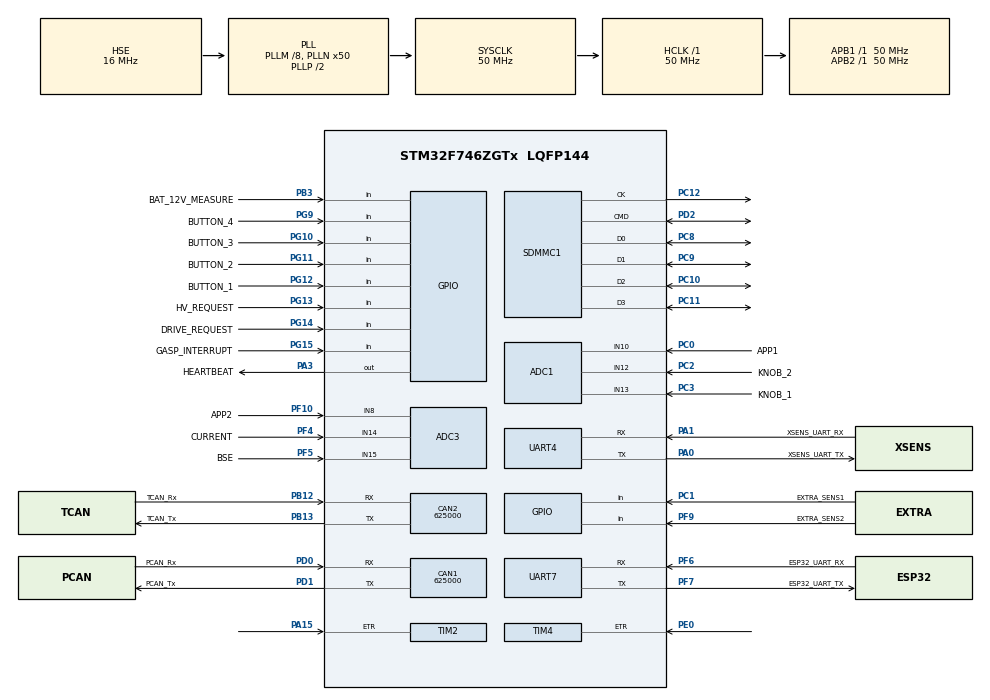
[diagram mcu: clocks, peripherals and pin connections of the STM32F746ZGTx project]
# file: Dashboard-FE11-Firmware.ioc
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ADC1.Channel-0\#ChannelRegularConversion=ADC_CHANNEL_10
ADC1.ClockPrescaler=ADC_CLOCK_SYNC_PCLK_DIV4
ADC1.NbrOfConversionFlag=1
ADC1.Rank-0\#ChannelRegularConversion=1
ADC1.SamplingTime-0\#ChannelRegularConversion=ADC_SAMPLETIME_3CYCLES
ADC1.master=1
ADC3.Channel-0\#ChannelRegularConversion=ADC_CHANNEL_14
ADC3.ClockPrescaler=ADC_CLOCK_SYNC_PCLK_DIV4
ADC3.NbrOfConversionFlag=1
ADC3.Rank-0\#ChannelRegularConversion=1
ADC3.SamplingTime-0\#ChannelRegularConversion=ADC_SAMPLETIME_3CYCLES
CAN1.BS1=CAN_BS1_3TQ
CAN1.BS2=CAN_BS2_1TQ
CAN1.CalculateBaudRate=625000
CAN1.CalculateTimeBit=1600
CAN1.CalculateTimeQuantum=320.0
CAN2.BS1=CAN_BS1_3TQ
CAN2.BS2=CAN_BS2_1TQ
CAN2.CalculateBaudRate=625000
CAN2.CalculateTimeBit=1600
CAN2.CalculateTimeQuantum=320.0
Mcu.Family=STM32F7
Mcu.Name=STM32F746ZGTx
Mcu.Package=LQFP144
NVIC.CAN1_RX0_IRQn=true\:0\:0\:false\:false\:true\:true\:true\:true
NVIC.CAN2_RX0_IRQn=true\:0\:0\:false\:false\:true\:true\:true\:true
NVIC.PriorityGroup=NVIC_PRIORITYGROUP_4
PA0/WKUP.GPIO_Label=XSENS_UART_TX
PA0/WKUP.Mode=Asynchronous
PA0/WKUP.Signal=UART4_TX
PA1.GPIO_Label=XSENS_UART_RX
PA1.Mode=Asynchronous
PA1.Signal=UART4_RX
PA13.Mode=Serial_Wire
PA13.Signal=SYS_JTMS-SWDIO
PA14.Mode=Serial_Wire
PA14.Signal=SYS_JTCK-SWCLK
PA15.Signal=S_TIM2_CH1_ETR
PA3.GPIO_Label=HEARTBEAT
PA3.Signal=GPIO_Output
PB12.GPIO_Label=TCAN_Rx
PB12.Mode=CAN_Activate
PB12.Signal=CAN2_RX
PB13.GPIO_Label=TCAN_Tx
PB13.Mode=CAN_Activate
PB13.Signal=CAN2_TX
PB3.GPIO_Label=BAT_12V_MEASURE
PB3.Signal=GPIO_Input
PC0.GPIO_Label=APP1
PC0.Signal=ADCx_IN10
PC1.GPIO_Label=EXTRA_SENS1
PC1.Signal=GPIO_Input
PC10.Mode=mmc_4_bits_Wide_bus
PC10.Signal=SDMMC1_D2
PC11.Mode=mmc_4_bits_Wide_bus
PC11.Signal=SDMMC1_D3
PC12.Mode=mmc_4_bits_Wide_bus
PC12.Signal=SDMMC1_CK
PC2.GPIO_Label=KNOB_2
PC2.Signal=ADCx_IN12
PC3.GPIO_Label=KNOB_1
PC3.Signal=ADCx_IN13
PC8.Mode=mmc_4_bits_Wide_bus
PC8.Signal=SDMMC1_D0
PC9.Mode=mmc_4_bits_Wide_bus
PC9.Signal=SDMMC1_D1
PD0.GPIO_Label=PCAN_Rx
PD0.Mode=CAN_Activate
PD0.Signal=CAN1_RX
PD1.GPIO_Label=PCAN_Tx
PD1.Mode=CAN_Activate
PD1.Signal=CAN1_TX
PD2.Mode=mmc_4_bits_Wide_bus
PD2.Signal=SDMMC1_CMD
PE0.Signal=S_TIM4_ETR
PF10.GPIO_Label=APP2
PF10.Mode=IN8
PF10.Signal=ADC3_IN8
PF4.GPIO_Label=CURRENT
PF4.Mode=IN14
PF4.Signal=ADC3_IN14
PF5.GPIO_Label=BSE
PF5.Mode=IN15
PF5.Signal=ADC3_IN15
PF6.GPIO_Label=ESP32_UART_RX
PF6.Mode=Asynchronous
PF6.Signal=UART7_RX
PF7.GPIO_Label=ESP32_UART_TX
PF7.Mode=Asynchronous
PF7.Signal=UART7_TX
PF9.GPIO_Label=EXTRA_SENS2
PF9.Signal=GPIO_Input
PG10.GPIO_Label=BUTTON_3
PG10.Signal=GPIO_Input
PG11.GPIO_Label=BUTTON_2
PG11.Signal=GPIO_Input
PG12.GPIO_Label=BUTTON_1
PG12.Signal=GPIO_Input
PG13.GPIO_Label=HV_REQUEST
PG13.Signal=GPIO_Input
PG14.GPIO_Label=DRIVE_REQUEST
PG14.Signal=GPIO_Input
PG15.GPIO_Label=GASP_INTERRUPT
PG15.Signal=GPIO_Input
PG9.GPIO_Label=BUTTON_4
PG9.Signal=GPIO_Input
PH0/OSC_IN.Mode=HSE-External-Oscillator
PH0/OSC_IN.Signal=RCC_OSC_IN
PH1/OSC_OUT.Mode=HSE-External-Oscillator
PH1/OSC_OUT.Signal=RCC_OSC_OUT
ProjectManager.HeapSize=0x200
ProjectManager.StackSize=0x400
ProjectManager.TargetToolchain=STM32CubeIDE
RCC.AHBFreq_Value=50000000
RCC.APB1Freq_Value=50000000
RCC.APB1TimFreq_Value=50000000
RCC.APB2Freq_Value=50000000
RCC.APB2TimFreq_Value=50000000
RCC.CECClockSelection=RCC_CECCLKSOURCE_HSI
RCC.CortexFreq_Value=50000000
RCC.HCLKFreq_Value=50000000
RCC.HSE_VALUE=16000000
RCC.HSI_VALUE=16000000
RCC.I2SCLockSelection=RCC_I2SCLKSOURCE_PLLI2S
RCC.OscillatorType=OscillatorTypeHSI|OscillatorTypeLSI|OscillatorTypeHSE|OscillatorTypeLSE
RCC.PLLM=8
RCC.PLLN=50
RCC.PLLSourceVirtual=RCC_PLLSOURCE_HSE
RCC.RTCClockSelection=RCC_RTCCLKSOURCE_LSI
RCC.SYSCLKFreq_VALUE=50000000
RCC.SYSCLKSource=RCC_SYSCLKSOURCE_PLLCLK
RCC.USBFreq_Value=50000000
RCC.VCOOutputFreq_Value=100000000
SH.ADCx_IN10.0=ADC1_IN10,IN10
SH.ADCx_IN12.0=ADC1_IN12,IN12
SH.ADCx_IN13.0=ADC1_IN13,IN13
SH.S_TIM2_CH1_ETR.0=TIM2_ETR,TriggerSource_ETR
SH.S_TIM4_ETR.0=TIM4_ETR,TriggerSource_ETR
VP_TIM2_VS_ControllerModeClock.Mode=Clock Mode
VP_TIM4_VS_ControllerModeClock.Mode=Clock Mode
board=custom

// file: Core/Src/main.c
/* USER CODE BEGIN Header */
/**
  ******************************************************************************
  * @file           : main.c
  * @brief          : Main program body
  ******************************************************************************
  * @attention
  *
  * Copyright (c) 2024 STMicroelectronics.
  * All rights reserved.
  *
  * This software is licensed under terms that can be found in the LICENSE file
  * in the root directory of this software component.
  * If no LICENSE file comes with this software, it is provided AS-IS.
  *
  ******************************************************************************
  */
/* USER CODE END Header */
#include "main.h"

ADC_HandleTypeDef hadc1;
ADC_HandleTypeDef hadc3;

CAN_HandleTypeDef hcan1;
CAN_HandleTypeDef hcan2;

CAN_RxHeaderTypeDef RxHeader;

MMC_HandleTypeDef hmmc1;

TIM_HandleTypeDef htim2;
TIM_HandleTypeDef htim4;

UART_HandleTypeDef huart4;
UART_HandleTypeDef huart7;

/* USER CODE BEGIN PV */
void HAL_CAN_RxFifo0MsgPendingCallback(CAN_HandleTypeDef *hcan) {
	HAL_CAN_GetRxMessage(&hcan1, CAN_RX_FIFO0, RxHeader, RxHeader);
		HAL_GPIO_TogglePin(GPIOB, GPIO_PIN_1);
}
/* USER CODE END PV */

void SystemClock_Config(void);
static void MX_GPIO_Init(void);
static void MX_UART4_Init(void);
static void MX_ADC1_Init(void);
static void MX_ADC3_Init(void);
static void MX_CAN1_Init(void);
static void MX_CAN2_Init(void);
static void MX_SDMMC1_MMC_Init(void);
static void MX_TIM2_Init(void);
static void MX_TIM4_Init(void);
static void MX_UART7_Init(void);

int main(void)
{

  /* MCU Configuration--------------------------------------------------------*/

  /* Reset of all peripherals, Initializes the Flash interface and the Systick. */
  HAL_Init();

  /* Configure the system clock */
  SystemClock_Config();

  /* Initialize all configured peripherals */
  MX_GPIO_Init();
  MX_UART4_Init();
  MX_ADC1_Init();
  MX_ADC3_Init();
  MX_CAN1_Init();
  MX_CAN2_Init();
  MX_SDMMC1_MMC_Init();
  MX_TIM2_Init();
  MX_TIM4_Init();
  MX_UART7_Init();

  /* Infinite loop */
  while (1)
  {

  }
}

void SystemClock_Config(void)
{
  RCC_OscInitTypeDef RCC_OscInitStruct = {0};
  RCC_ClkInitTypeDef RCC_ClkInitStruct = {0};

  /** Configure the main internal regulator output voltage
  */
  __HAL_RCC_PWR_CLK_ENABLE();
  __HAL_PWR_VOLTAGESCALING_CONFIG(PWR_REGULATOR_VOLTAGE_SCALE3);

  /** Initializes the RCC Oscillators according to the specified parameters
  * in the RCC_OscInitTypeDef structure.
  */
  RCC_OscInitStruct.OscillatorType = OscillatorTypeHSI|OscillatorTypeLSI
                              |OscillatorTypeHSE|OscillatorTypeLSE;
  RCC_OscInitStruct.HSEState = RCC_HSE_ON;
  RCC_OscInitStruct.PLL.PLLState = RCC_PLL_ON;
  RCC_OscInitStruct.PLL.PLLSource = RCC_PLLSOURCE_HSE;
  RCC_OscInitStruct.PLL.PLLM = 8;
  RCC_OscInitStruct.PLL.PLLN = 50;
  RCC_OscInitStruct.PLL.PLLP = RCC_PLLP_DIV2;
  RCC_OscInitStruct.PLL.PLLQ = 2;
  if (HAL_RCC_OscConfig(&RCC_OscInitStruct) != HAL_OK)
  {
    Error_Handler();
  }

  /** Activate the Over-Drive mode
  */
  if (HAL_PWREx_EnableOverDrive() != HAL_OK)
  {
    Error_Handler();
  }

  /** Initializes the CPU, AHB and APB buses clocks
  */
  RCC_ClkInitStruct.ClockType = RCC_CLOCKTYPE_HCLK|RCC_CLOCKTYPE_SYSCLK
                              |RCC_CLOCKTYPE_PCLK1|RCC_CLOCKTYPE_PCLK2;
  RCC_ClkInitStruct.SYSCLKSource = RCC_SYSCLKSOURCE_PLLCLK;
  RCC_ClkInitStruct.AHBCLKDivider = RCC_SYSCLK_DIV1;
  RCC_ClkInitStruct.APB1CLKDivider = RCC_HCLK_DIV1;
  RCC_ClkInitStruct.APB2CLKDivider = RCC_HCLK_DIV1;

  if (HAL_RCC_ClockConfig(&RCC_ClkInitStruct, FLASH_LATENCY_1) != HAL_OK)
  {
    Error_Handler();
  }
}

static void MX_ADC1_Init(void)
{

  ADC_ChannelConfTypeDef sConfig = {0};

  /** Configure the global features of the ADC (Clock, Resolution, Data Alignment and number of conversion)
  */
  hadc1.Instance = ADC1;
  hadc1.Init.ClockPrescaler = ADC_CLOCK_SYNC_PCLK_DIV4;
  hadc1.Init.Resolution = ADC_RESOLUTION_12B;
  hadc1.Init.ScanConvMode = ADC_SCAN_DISABLE;
  hadc1.Init.ContinuousConvMode = DISABLE;
  hadc1.Init.DiscontinuousConvMode = DISABLE;
  hadc1.Init.ExternalTrigConvEdge = ADC_EXTERNALTRIGCONVEDGE_NONE;
  hadc1.Init.ExternalTrigConv = ADC_SOFTWARE_START;
  hadc1.Init.DataAlign = ADC_DATAALIGN_RIGHT;
  hadc1.Init.NbrOfConversion = 1;
  hadc1.Init.DMAContinuousRequests = DISABLE;
  hadc1.Init.EOCSelection = ADC_EOC_SINGLE_CONV;
  if (HAL_ADC_Init(&hadc1) != HAL_OK)
  {
    Error_Handler();
  }

  /** Configure for the selected ADC regular channel its corresponding rank in the sequencer and its sample time.
  */
  sConfig.Channel = ADC_CHANNEL_10;
  sConfig.Rank = ADC_REGULAR_RANK_1;
  sConfig.SamplingTime = ADC_SAMPLETIME_3CYCLES;
  if (HAL_ADC_ConfigChannel(&hadc1, &sConfig) != HAL_OK)
  {
    Error_Handler();
  }

}

static void MX_ADC3_Init(void)
{

  ADC_ChannelConfTypeDef sConfig = {0};

  /** Configure the global features of the ADC (Clock, Resolution, Data Alignment and number of conversion)
  */
  hadc3.Instance = ADC3;
  hadc3.Init.ClockPrescaler = ADC_CLOCK_SYNC_PCLK_DIV4;
  hadc3.Init.Resolution = ADC_RESOLUTION_12B;
  hadc3.Init.ScanConvMode = ADC_SCAN_DISABLE;
  hadc3.Init.ContinuousConvMode = DISABLE;
  hadc3.Init.DiscontinuousConvMode = DISABLE;
  hadc3.Init.ExternalTrigConvEdge = ADC_EXTERNALTRIGCONVEDGE_NONE;
  hadc3.Init.ExternalTrigConv = ADC_SOFTWARE_START;
  hadc3.Init.DataAlign = ADC_DATAALIGN_RIGHT;
  hadc3.Init.NbrOfConversion = 1;
  hadc3.Init.DMAContinuousRequests = DISABLE;
  hadc3.Init.EOCSelection = ADC_EOC_SINGLE_CONV;
  if (HAL_ADC_Init(&hadc3) != HAL_OK)
  {
    Error_Handler();
  }

  /** Configure for the selected ADC regular channel its corresponding rank in the sequencer and its sample time.
  */
  sConfig.Channel = ADC_CHANNEL_14;
  sConfig.Rank = ADC_REGULAR_RANK_1;
  sConfig.SamplingTime = ADC_SAMPLETIME_3CYCLES;
  if (HAL_ADC_ConfigChannel(&hadc3, &sConfig) != HAL_OK)
  {
    Error_Handler();
  }

}

static void MX_CAN1_Init(void)
{

  hcan1.Instance = CAN1;
  hcan1.Init.Prescaler = 16;
  hcan1.Init.Mode = CAN_MODE_NORMAL;
  hcan1.Init.SyncJumpWidth = CAN_SJW_1TQ;
  hcan1.Init.TimeSeg1 = CAN_BS1_3TQ;
  hcan1.Init.TimeSeg2 = CAN_BS2_1TQ;
  hcan1.Init.TimeTriggeredMode = DISABLE;
  hcan1.Init.AutoBusOff = DISABLE;
  hcan1.Init.AutoWakeUp = DISABLE;
  hcan1.Init.AutoRetransmission = DISABLE;
  hcan1.Init.ReceiveFifoLocked = DISABLE;
  hcan1.Init.TransmitFifoPriority = DISABLE;
  if (HAL_CAN_Init(&hcan1) != HAL_OK)
  {
    Error_Handler();
  }

}

static void MX_CAN2_Init(void)
{

  hcan2.Instance = CAN2;
  hcan2.Init.Prescaler = 16;
  hcan2.Init.Mode = CAN_MODE_NORMAL;
  hcan2.Init.SyncJumpWidth = CAN_SJW_1TQ;
  hcan2.Init.TimeSeg1 = CAN_BS1_3TQ;
  hcan2.Init.TimeSeg2 = CAN_BS2_1TQ;
  hcan2.Init.TimeTriggeredMode = DISABLE;
  hcan2.Init.AutoBusOff = DISABLE;
  hcan2.Init.AutoWakeUp = DISABLE;
  hcan2.Init.AutoRetransmission = DISABLE;
  hcan2.Init.ReceiveFifoLocked = DISABLE;
  hcan2.Init.TransmitFifoPriority = DISABLE;
  if (HAL_CAN_Init(&hcan2) != HAL_OK)
  {
    Error_Handler();
  }

}

static void MX_SDMMC1_MMC_Init(void)
{

  hmmc1.Instance = SDMMC1;
  hmmc1.Init.ClockEdge = SDMMC_CLOCK_EDGE_RISING;
  hmmc1.Init.ClockBypass = SDMMC_CLOCK_BYPASS_DISABLE;
  hmmc1.Init.ClockPowerSave = SDMMC_CLOCK_POWER_SAVE_DISABLE;
  hmmc1.Init.BusWide = SDMMC_BUS_WIDE_4B;
  hmmc1.Init.HardwareFlowControl = SDMMC_HARDWARE_FLOW_CONTROL_DISABLE;
  hmmc1.Init.ClockDiv = 0;
  if (HAL_MMC_Init(&hmmc1) != HAL_OK)
  {
    Error_Handler();
  }
  if (HAL_MMC_ConfigWideBusOperation(&hmmc1, SDMMC_BUS_WIDE_4B) != HAL_OK)
  {
    Error_Handler();
  }

}

static void MX_TIM2_Init(void)
{

  TIM_SlaveConfigTypeDef sSlaveConfig = {0};
  TIM_MasterConfigTypeDef sMasterConfig = {0};

  htim2.Instance = TIM2;
  htim2.Init.Prescaler = 0;
  htim2.Init.CounterMode = TIM_COUNTERMODE_UP;
  htim2.Init.Period = 4294967295;
  htim2.Init.ClockDivision = TIM_CLOCKDIVISION_DIV1;
  htim2.Init.AutoReloadPreload = TIM_AUTORELOAD_PRELOAD_DISABLE;
  if (HAL_TIM_Base_Init(&htim2) != HAL_OK)
  {
    Error_Handler();
  }
  sSlaveConfig.SlaveMode = TIM_SLAVEMODE_EXTERNAL1;
  sSlaveConfig.InputTrigger = TIM_TS_ETRF;
  sSlaveConfig.TriggerPolarity = TIM_TRIGGERPOLARITY_NONINVERTED;
  sSlaveConfig.TriggerPrescaler = TIM_TRIGGERPRESCALER_DIV1;
  sSlaveConfig.TriggerFilter = 0;
  if (HAL_TIM_SlaveConfigSynchro(&htim2, &sSlaveConfig) != HAL_OK)
  {
    Error_Handler();
  }
  sMasterConfig.MasterOutputTrigger = TIM_TRGO_RESET;
  sMasterConfig.MasterSlaveMode = TIM_MASTERSLAVEMODE_DISABLE;
  if (HAL_TIMEx_MasterConfigSynchronization(&htim2, &sMasterConfig) != HAL_OK)
  {
    Error_Handler();
  }

}

static void MX_TIM4_Init(void)
{

  TIM_SlaveConfigTypeDef sSlaveConfig = {0};
  TIM_MasterConfigTypeDef sMasterConfig = {0};

  htim4.Instance = TIM4;
  htim4.Init.Prescaler = 0;
  htim4.Init.CounterMode = TIM_COUNTERMODE_UP;
  htim4.Init.Period = 65535;
  htim4.Init.ClockDivision = TIM_CLOCKDIVISION_DIV1;
  htim4.Init.AutoReloadPreload = TIM_AUTORELOAD_PRELOAD_DISABLE;
  if (HAL_TIM_Base_Init(&htim4) != HAL_OK)
  {
    Error_Handler();
  }
  sSlaveConfig.SlaveMode = TIM_SLAVEMODE_EXTERNAL1;
  sSlaveConfig.InputTrigger = TIM_TS_ETRF;
  sSlaveConfig.TriggerPolarity = TIM_TRIGGERPOLARITY_NONINVERTED;
  sSlaveConfig.TriggerPrescaler = TIM_TRIGGERPRESCALER_DIV1;
  sSlaveConfig.TriggerFilter = 0;
  if (HAL_TIM_SlaveConfigSynchro(&htim4, &sSlaveConfig) != HAL_OK)
  {
    Error_Handler();
  }
  sMasterConfig.MasterOutputTrigger = TIM_TRGO_RESET;
  sMasterConfig.MasterSlaveMode = TIM_MASTERSLAVEMODE_DISABLE;
  if (HAL_TIMEx_MasterConfigSynchronization(&htim4, &sMasterConfig) != HAL_OK)
  {
    Error_Handler();
  }

}

static void MX_UART4_Init(void)
{

  huart4.Instance = UART4;
  huart4.Init.BaudRate = 115200;
  huart4.Init.WordLength = UART_WORDLENGTH_8B;
  huart4.Init.StopBits = UART_STOPBITS_1;
  huart4.Init.Parity = UART_PARITY_NONE;
  huart4.Init.Mode = UART_MODE_TX_RX;
  huart4.Init.HwFlowCtl = UART_HWCONTROL_NONE;
  huart4.Init.OverSampling = UART_OVERSAMPLING_16;
  huart4.Init.OneBitSampling = UART_ONE_BIT_SAMPLE_DISABLE;
  huart4.AdvancedInit.AdvFeatureInit = UART_ADVFEATURE_NO_INIT;
  if (HAL_UART_Init(&huart4) != HAL_OK)
  {
    Error_Handler();
  }

}

static void MX_UART7_Init(void)
{

  huart7.Instance = UART7;
  huart7.Init.BaudRate = 115200;
  huart7.Init.WordLength = UART_WORDLENGTH_8B;
  huart7.Init.StopBits = UART_STOPBITS_1;
  huart7.Init.Parity = UART_PARITY_NONE;
  huart7.Init.Mode = UART_MODE_TX_RX;
  huart7.Init.HwFlowCtl = UART_HWCONTROL_NONE;
  huart7.Init.OverSampling = UART_OVERSAMPLING_16;
  huart7.Init.OneBitSampling = UART_ONE_BIT_SAMPLE_DISABLE;
  huart7.AdvancedInit.AdvFeatureInit = UART_ADVFEATURE_NO_INIT;
  if (HAL_UART_Init(&huart7) != HAL_OK)
  {
    Error_Handler();
  }

}

static void MX_GPIO_Init(void)
{
  GPIO_InitTypeDef GPIO_InitStruct = {0};

  /* GPIO Ports Clock Enable */
  __HAL_RCC_GPIOF_CLK_ENABLE();
  __HAL_RCC_GPIOH_CLK_ENABLE();
  __HAL_RCC_GPIOC_CLK_ENABLE();
  __HAL_RCC_GPIOA_CLK_ENABLE();
  __HAL_RCC_GPIOB_CLK_ENABLE();
  __HAL_RCC_GPIOD_CLK_ENABLE();
  __HAL_RCC_GPIOG_CLK_ENABLE();
  __HAL_RCC_GPIOE_CLK_ENABLE();

  /*Configure GPIO pin Output Level */
  HAL_GPIO_WritePin(HEARTBEAT_GPIO_Port, HEARTBEAT_Pin, GPIO_PIN_RESET);

  /*Configure GPIO pin : EXTRA_SENS2_Pin */
  GPIO_InitStruct.Pin = EXTRA_SENS2_Pin;
  GPIO_InitStruct.Mode = GPIO_MODE_INPUT;
  GPIO_InitStruct.Pull = GPIO_NOPULL;
  HAL_GPIO_Init(EXTRA_SENS2_GPIO_Port, &GPIO_InitStruct);

  /*Configure GPIO pin : EXTRA_SENS1_Pin */
  GPIO_InitStruct.Pin = EXTRA_SENS1_Pin;
  GPIO_InitStruct.Mode = GPIO_MODE_INPUT;
  GPIO_InitStruct.Pull = GPIO_NOPULL;
  HAL_GPIO_Init(EXTRA_SENS1_GPIO_Port, &GPIO_InitStruct);

  /*Configure GPIO pin : HEARTBEAT_Pin */
  GPIO_InitStruct.Pin = HEARTBEAT_Pin;
  GPIO_InitStruct.Mode = GPIO_MODE_OUTPUT_PP;
  GPIO_InitStruct.Pull = GPIO_NOPULL;
  GPIO_InitStruct.Speed = GPIO_SPEED_FREQ_LOW;
  HAL_GPIO_Init(HEARTBEAT_GPIO_Port, &GPIO_InitStruct);

  /*Configure GPIO pins : BUTTON_4_Pin BUTTON_3_Pin BUTTON_2_Pin BUTTON_1_Pin
                           HV_REQUEST_Pin DRIVE_REQUEST_Pin GASP_INTERRUPT_Pin */
  GPIO_InitStruct.Pin = BUTTON_4_Pin|BUTTON_3_Pin|BUTTON_2_Pin|BUTTON_1_Pin
                          |HV_REQUEST_Pin|DRIVE_REQUEST_Pin|GASP_INTERRUPT_Pin;
  GPIO_InitStruct.Mode = GPIO_MODE_INPUT;
  GPIO_InitStruct.Pull = GPIO_NOPULL;
  HAL_GPIO_Init(GPIOG, &GPIO_InitStruct);

  /*Configure GPIO pin : BAT_12V_MEASURE_Pin */
  GPIO_InitStruct.Pin = BAT_12V_MEASURE_Pin;
  GPIO_InitStruct.Mode = GPIO_MODE_INPUT;
  GPIO_InitStruct.Pull = GPIO_NOPULL;
  HAL_GPIO_Init(BAT_12V_MEASURE_GPIO_Port, &GPIO_InitStruct);

}

void Error_Handler(void)
{
  __disable_irq();
  while (1)
  {
  }
}
